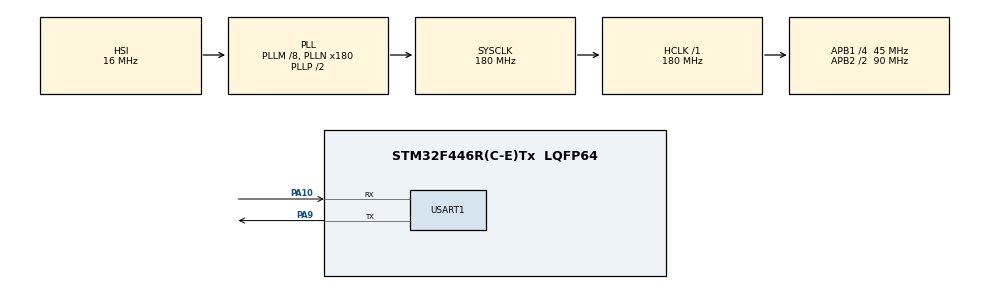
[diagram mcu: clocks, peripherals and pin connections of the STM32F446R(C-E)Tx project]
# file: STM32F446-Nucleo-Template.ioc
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Mcu.Family=STM32F4
Mcu.Name=STM32F446R(C-E)Tx
Mcu.Package=LQFP64
NVIC.PriorityGroup=NVIC_PRIORITYGROUP_0
PA10.Mode=Asynchronous
PA10.Signal=USART1_RX
PA13.Mode=JTAG_4_pins
PA13.Signal=SYS_JTMS-SWDIO
PA14.Mode=JTAG_4_pins
PA14.Signal=SYS_JTCK-SWCLK
PA15.Mode=JTAG_4_pins
PA15.Signal=SYS_JTDI
PA9.Mode=Asynchronous
PA9.Signal=USART1_TX
PB3.Mode=JTAG_4_pins
PB3.Signal=SYS_JTDO-SWO
ProjectManager.HeapSize=0x200
ProjectManager.StackSize=0x400
ProjectManager.TargetToolchain=Makefile
RCC.48MHZClocksFreq_Value=84000000
RCC.AHBFreq_Value=180000000
RCC.APB1CLKDivider=RCC_HCLK_DIV4
RCC.APB1Freq_Value=45000000
RCC.APB1TimFreq_Value=90000000
RCC.APB2CLKDivider=RCC_HCLK_DIV2
RCC.APB2Freq_Value=90000000
RCC.APB2TimFreq_Value=180000000
RCC.CortexFreq_Value=180000000
RCC.FLatency-AdvancedSettings=FLASH_LATENCY_5
RCC.HCLKFreq_Value=180000000
RCC.HSE_VALUE=8000000
RCC.HSI_VALUE=16000000
RCC.PLLM=8
RCC.PLLN=180
RCC.SYSCLKFreq_VALUE=180000000
RCC.SYSCLKSource=RCC_SYSCLKSOURCE_PLLCLK
RCC.USBFreq_Value=180000000
RCC.VCOOutputFreq_Value=360000000
USART1.VirtualMode=VM_ASYNC
board=NUCLEO-F446RE

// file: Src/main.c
/* USER CODE BEGIN Header */
/**
  ******************************************************************************
  * @file           : main.c
  * @brief          : Main program body
  ******************************************************************************
  * @attention
  *
  * Copyright (c) 2022 STMicroelectronics.
  * All rights reserved.
  *
  * This software is licensed under terms that can be found in the LICENSE file
  * in the root directory of this software component.
  * If no LICENSE file comes with this software, it is provided AS-IS.
  *
  ******************************************************************************
  */
/* USER CODE END Header */
#include "main.h"
#include "usart.h"
#include "gpio.h"

/* USER CODE BEGIN PV */
// CAsting here to uint8_t which for this case is the same as a char
const uint8_t* message_HelloWorld = (uint8_t*)"Hello World\n";
const uint16_t size_HelloWorld = (12);
/* USER CODE END PV */

void SystemClock_Config(void);

int main(void)
{

  /* MCU Configuration--------------------------------------------------------*/

  /* Reset of all peripherals, Initializes the Flash interface and the Systick. */
  HAL_Init();

  /* Configure the system clock */
  SystemClock_Config();

  /* Initialize all configured peripherals */
  MX_GPIO_Init();
  MX_USART1_UART_Init();

  /* Infinite loop */
  while (1)
  {
        // Blocking UART Tx
    HAL_UART_Transmit(&huart1, message_HelloWorld, size_HelloWorld, 1);
    // Transmit string every 1 second.
    HAL_Delay(1000);
  }
}

void SystemClock_Config(void)
{
  #if !defined(RENODE_SIMULATION)

  RCC_OscInitTypeDef RCC_OscInitStruct = {0};
  RCC_ClkInitTypeDef RCC_ClkInitStruct = {0};

  /** Configure the main internal regulator output voltage
  */
  __HAL_RCC_PWR_CLK_ENABLE();
  __HAL_PWR_VOLTAGESCALING_CONFIG(PWR_REGULATOR_VOLTAGE_SCALE1);

  /** Initializes the RCC Oscillators according to the specified parameters
  * in the RCC_OscInitTypeDef structure.
  */
  RCC_OscInitStruct.OscillatorType = RCC_OSCILLATORTYPE_HSI;
  RCC_OscInitStruct.HSIState = RCC_HSI_ON;
  RCC_OscInitStruct.HSICalibrationValue = RCC_HSICALIBRATION_DEFAULT;
  RCC_OscInitStruct.PLL.PLLState = RCC_PLL_ON;
  RCC_OscInitStruct.PLL.PLLSource = RCC_PLLSOURCE_HSI;
  RCC_OscInitStruct.PLL.PLLM = 8;
  RCC_OscInitStruct.PLL.PLLN = 180;
  RCC_OscInitStruct.PLL.PLLP = RCC_PLLP_DIV2;
  RCC_OscInitStruct.PLL.PLLQ = 2;
  RCC_OscInitStruct.PLL.PLLR = 2;
  if (HAL_RCC_OscConfig(&RCC_OscInitStruct) != HAL_OK)
  {
    Error_Handler();
  }

  /** Activate the Over-Drive mode
  */
  if (HAL_PWREx_EnableOverDrive() != HAL_OK)
  {
    Error_Handler();
  }

  /** Initializes the CPU, AHB and APB buses clocks
  */
  RCC_ClkInitStruct.ClockType = RCC_CLOCKTYPE_HCLK|RCC_CLOCKTYPE_SYSCLK
                              |RCC_CLOCKTYPE_PCLK1|RCC_CLOCKTYPE_PCLK2;
  RCC_ClkInitStruct.SYSCLKSource = RCC_SYSCLKSOURCE_PLLCLK;
  RCC_ClkInitStruct.AHBCLKDivider = RCC_SYSCLK_DIV1;
  RCC_ClkInitStruct.APB1CLKDivider = RCC_HCLK_DIV4;
  RCC_ClkInitStruct.APB2CLKDivider = RCC_HCLK_DIV2;

  if (HAL_RCC_ClockConfig(&RCC_ClkInitStruct, FLASH_LATENCY_5) != HAL_OK)
  {
    Error_Handler();
  }
  #endif
}

void Error_Handler(void)
{
  __disable_irq();
  while (1)
  {
  }
}
